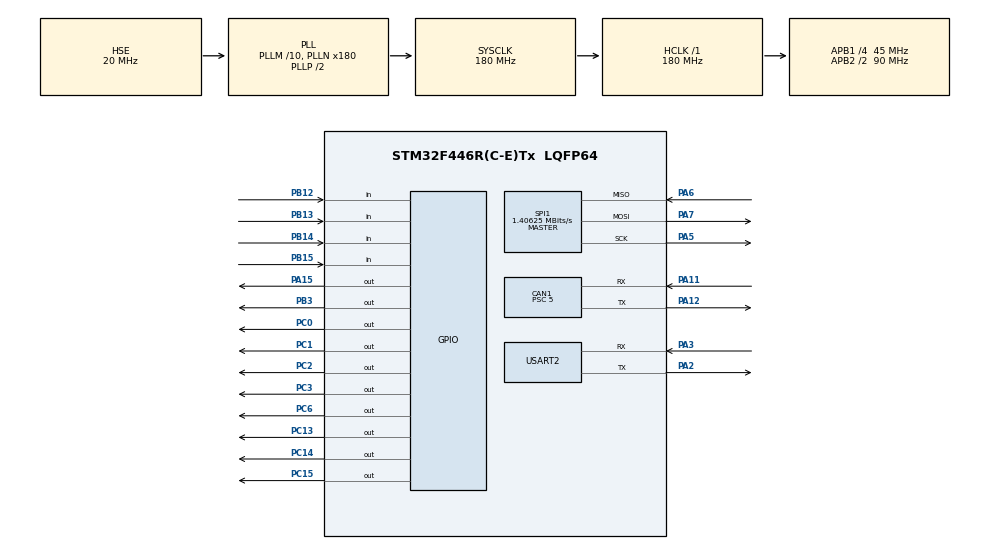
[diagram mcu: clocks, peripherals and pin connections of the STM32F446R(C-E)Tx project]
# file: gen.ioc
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CAN1.ABOM=ENABLE
CAN1.AWUM=ENABLE
CAN1.BS1=CAN_BS1_13TQ
CAN1.BS2=CAN_BS2_2TQ
CAN1.CalculateTimeQuantum=111.11111111111111
CAN1.NART=ENABLE
CAN1.Prescaler=5
Dma.Request0=SPI1_RX
Dma.Request1=SPI1_TX
Dma.Request2=USART2_RX
Dma.Request3=USART2_TX
Dma.SPI1_RX.0.Direction=DMA_PERIPH_TO_MEMORY
Dma.SPI1_RX.0.FIFOMode=DMA_FIFOMODE_DISABLE
Dma.SPI1_RX.0.Instance=DMA2_Stream0
Dma.SPI1_RX.0.MemDataAlignment=DMA_MDATAALIGN_BYTE
Dma.SPI1_RX.0.MemInc=DMA_MINC_ENABLE
Dma.SPI1_RX.0.Mode=DMA_NORMAL
Dma.SPI1_RX.0.PeriphDataAlignment=DMA_PDATAALIGN_BYTE
Dma.SPI1_RX.0.PeriphInc=DMA_PINC_DISABLE
Dma.SPI1_RX.0.Priority=DMA_PRIORITY_LOW
Dma.SPI1_TX.1.Direction=DMA_MEMORY_TO_PERIPH
Dma.SPI1_TX.1.FIFOMode=DMA_FIFOMODE_DISABLE
Dma.SPI1_TX.1.Instance=DMA2_Stream3
Dma.SPI1_TX.1.MemDataAlignment=DMA_MDATAALIGN_BYTE
Dma.SPI1_TX.1.MemInc=DMA_MINC_ENABLE
Dma.SPI1_TX.1.Mode=DMA_NORMAL
Dma.SPI1_TX.1.PeriphDataAlignment=DMA_PDATAALIGN_BYTE
Dma.SPI1_TX.1.PeriphInc=DMA_PINC_DISABLE
Dma.SPI1_TX.1.Priority=DMA_PRIORITY_LOW
Dma.USART2_RX.2.Direction=DMA_PERIPH_TO_MEMORY
Dma.USART2_RX.2.FIFOMode=DMA_FIFOMODE_DISABLE
Dma.USART2_RX.2.Instance=DMA1_Stream5
Dma.USART2_RX.2.MemDataAlignment=DMA_MDATAALIGN_BYTE
Dma.USART2_RX.2.MemInc=DMA_MINC_ENABLE
Dma.USART2_RX.2.Mode=DMA_NORMAL
Dma.USART2_RX.2.PeriphDataAlignment=DMA_PDATAALIGN_BYTE
Dma.USART2_RX.2.PeriphInc=DMA_PINC_DISABLE
Dma.USART2_RX.2.Priority=DMA_PRIORITY_LOW
Dma.USART2_TX.3.Direction=DMA_MEMORY_TO_PERIPH
Dma.USART2_TX.3.FIFOMode=DMA_FIFOMODE_DISABLE
Dma.USART2_TX.3.Instance=DMA1_Stream6
Dma.USART2_TX.3.MemDataAlignment=DMA_MDATAALIGN_BYTE
Dma.USART2_TX.3.MemInc=DMA_MINC_ENABLE
Dma.USART2_TX.3.Mode=DMA_NORMAL
Dma.USART2_TX.3.PeriphDataAlignment=DMA_PDATAALIGN_BYTE
Dma.USART2_TX.3.PeriphInc=DMA_PINC_DISABLE
Dma.USART2_TX.3.Priority=DMA_PRIORITY_LOW
FREERTOS.INCLUDE_vTaskDelayUntil=1
FREERTOS.MEMORY_ALLOCATION=1
FREERTOS.Tasks01=LineCalcTask,0,2048,StartLineCalcTask,Default,NULL,Static,LineCalcTaskBuffer,LineCalcTaskControlBlock
FREERTOS.configCHECK_FOR_STACK_OVERFLOW=1
FREERTOS.configUSE_TRACE_FACILITY=1
Mcu.Family=STM32F4
Mcu.Name=STM32F446R(C-E)Tx
Mcu.Package=LQFP64
NVIC.CAN1_RX0_IRQn=true\:5\:0\:false\:false\:true\:true\:true\:true
NVIC.CAN1_TX_IRQn=true\:5\:0\:false\:false\:true\:true\:true\:true
NVIC.DMA1_Stream5_IRQn=true\:5\:0\:false\:false\:true\:true\:false\:true
NVIC.DMA1_Stream6_IRQn=true\:5\:0\:false\:false\:true\:true\:false\:true
NVIC.DMA2_Stream0_IRQn=true\:5\:0\:false\:false\:true\:true\:false\:true
NVIC.DMA2_Stream3_IRQn=true\:5\:0\:false\:false\:true\:true\:false\:true
NVIC.PriorityGroup=NVIC_PRIORITYGROUP_4
NVIC.SPI1_IRQn=true\:5\:0\:false\:false\:true\:true\:true\:true
NVIC.TIM2_IRQn=true\:0\:0\:false\:false\:true\:false\:false\:true
NVIC.TimeBase=TIM2_IRQn
NVIC.TimeBaseIP=TIM2
NVIC.USART2_IRQn=true\:5\:0\:false\:false\:true\:true\:true\:true
PA11.Mode=Master
PA11.Signal=CAN1_RX
PA12.Mode=Master
PA12.Signal=CAN1_TX
PA13.Signal=SYS_JTMS-SWDIO
PA14.Signal=SYS_JTCK-SWCLK
PA15.Signal=GPIO_Output
PA2.Mode=Asynchronous
PA2.Signal=USART2_TX
PA3.Mode=Asynchronous
PA3.Signal=USART2_RX
PA5.Mode=Full_Duplex_Master
PA5.Signal=SPI1_SCK
PA6.Mode=Full_Duplex_Master
PA6.Signal=SPI1_MISO
PA7.Mode=Full_Duplex_Master
PA7.Signal=SPI1_MOSI
PB12.Signal=GPIO_Input
PB13.Signal=GPIO_Input
PB14.Signal=GPIO_Input
PB15.Signal=GPIO_Input
PB3.Signal=GPIO_Output
PC0.Signal=GPIO_Output
PC1.Signal=GPIO_Output
PC13.Signal=GPIO_Output
PC14-OSC32_IN.Signal=GPIO_Output
PC15-OSC32_OUT.Signal=GPIO_Output
PC2.Signal=GPIO_Output
PC3.Signal=GPIO_Output
PC6.Signal=GPIO_Output
PH0-OSC_IN.Mode=HSE-External-Oscillator
PH0-OSC_IN.Signal=RCC_OSC_IN
PH1-OSC_OUT.Mode=HSE-External-Oscillator
PH1-OSC_OUT.Signal=RCC_OSC_OUT
ProjectManager.HeapSize=0x200
ProjectManager.StackSize=0x400
ProjectManager.TargetToolchain=SW4STM32
RCC.AHBFreq_Value=180000000
RCC.APB1CLKDivider=RCC_HCLK_DIV4
RCC.APB1Freq_Value=45000000
RCC.APB1TimFreq_Value=90000000
RCC.APB2CLKDivider=RCC_HCLK_DIV2
RCC.APB2Freq_Value=90000000
RCC.APB2TimFreq_Value=180000000
RCC.CortexFreq_Value=180000000
RCC.HCLKFreq_Value=180000000
RCC.HSE_VALUE=20000000
RCC.HSICalibrationValue=16
RCC.PLLM=10
RCC.PLLN=180
RCC.PLLSourceVirtual=RCC_PLLSOURCE_HSE
RCC.RCC_TIM_PRescaler_Selection=RCC_TIMPRES_DESACTIVATED
RCC.SYSCLKFreq_VALUE=180000000
RCC.SYSCLKSource=RCC_SYSCLKSOURCE_PLLCLK
RCC.USBFreq_Value=180000000
RCC.VCOOutputFreq_Value=360000000
SPI1.BaudRatePrescaler=SPI_BAUDRATEPRESCALER_64
SPI1.CalculateBaudRate=1.40625 MBits/s
SPI1.Direction=SPI_DIRECTION_2LINES
SPI1.Mode=SPI_MODE_MASTER
SPI1.VirtualType=VM_MASTER
USART2.VirtualMode=VM_ASYNC
VP_FREERTOS_VS_CMSIS_V1.Mode=CMSIS_V1
VP_SYS_VS_tim2.Mode=TIM2
board=gen

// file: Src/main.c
/* USER CODE BEGIN Header */
/**
  ******************************************************************************
  * @file           : main.c
  * @brief          : Main program body
  ******************************************************************************
  * @attention
  *
  * <h2><center>&copy; Copyright (c) 2020 STMicroelectronics.
  * All rights reserved.</center></h2>
  *
  * This software component is licensed by ST under Ultimate Liberty license
  * SLA0044, the "License"; You may not use this file except in compliance with
  * the License. You may obtain a copy of the License at:
  *                             www.st.com/SLA0044
  *
  ******************************************************************************
  */
/* USER CODE END Header */

#include "main.h"
#include "cmsis_os.h"
#include "can.h"
#include "dma.h"
#include "spi.h"
#include "usart.h"
#include "gpio.h"

/* USER CODE BEGIN Includes */
#include <system_init.h>
/* USER CODE END Includes */

void SystemClock_Config(void);
void MX_FREERTOS_Init(void);

int main(void)
{

  /* MCU Configuration--------------------------------------------------------*/

  /* Reset of all peripherals, Initializes the Flash interface and the Systick. */
  HAL_Init();

  /* Configure the system clock */
  SystemClock_Config();

  /* USER CODE BEGIN SysInit */
  system_init();
  /* USER CODE END SysInit */

  /* Initialize all configured peripherals */
  MX_GPIO_Init();
  MX_DMA_Init();
  MX_SPI1_Init();
  MX_CAN1_Init();
  MX_USART2_UART_Init();
  /* USER CODE BEGIN 2 */
  can_start();
  /* USER CODE END 2 */

  /* Call init function for freertos objects (in freertos.c) */
  MX_FREERTOS_Init();

  /* Start scheduler */
  osKernelStart();

  /* We should never get here as control is now taken by the scheduler */

  /* Infinite loop */
  while (1)
  {

  }
}

void SystemClock_Config(void)
{
  RCC_OscInitTypeDef RCC_OscInitStruct = {0};
  RCC_ClkInitTypeDef RCC_ClkInitStruct = {0};

  /** Configure the main internal regulator output voltage
  */
  __HAL_RCC_PWR_CLK_ENABLE();
  __HAL_PWR_VOLTAGESCALING_CONFIG(PWR_REGULATOR_VOLTAGE_SCALE1);
  /** Initializes the CPU, AHB and APB busses clocks
  */
  RCC_OscInitStruct.OscillatorType = RCC_OSCILLATORTYPE_HSE;
  RCC_OscInitStruct.HSEState = RCC_HSE_ON;
  RCC_OscInitStruct.PLL.PLLState = RCC_PLL_ON;
  RCC_OscInitStruct.PLL.PLLSource = RCC_PLLSOURCE_HSE;
  RCC_OscInitStruct.PLL.PLLM = 10;
  RCC_OscInitStruct.PLL.PLLN = 180;
  RCC_OscInitStruct.PLL.PLLP = RCC_PLLP_DIV2;
  RCC_OscInitStruct.PLL.PLLQ = 2;
  RCC_OscInitStruct.PLL.PLLR = 2;
  if (HAL_RCC_OscConfig(&RCC_OscInitStruct) != HAL_OK)
  {
    Error_Handler();
  }
  /** Activate the Over-Drive mode
  */
  if (HAL_PWREx_EnableOverDrive() != HAL_OK)
  {
    Error_Handler();
  }
  /** Initializes the CPU, AHB and APB busses clocks
  */
  RCC_ClkInitStruct.ClockType = RCC_CLOCKTYPE_HCLK|RCC_CLOCKTYPE_SYSCLK
                              |RCC_CLOCKTYPE_PCLK1|RCC_CLOCKTYPE_PCLK2;
  RCC_ClkInitStruct.SYSCLKSource = RCC_SYSCLKSOURCE_PLLCLK;
  RCC_ClkInitStruct.AHBCLKDivider = RCC_SYSCLK_DIV1;
  RCC_ClkInitStruct.APB1CLKDivider = RCC_HCLK_DIV4;
  RCC_ClkInitStruct.APB2CLKDivider = RCC_HCLK_DIV2;

  if (HAL_RCC_ClockConfig(&RCC_ClkInitStruct, FLASH_LATENCY_5) != HAL_OK)
  {
    Error_Handler();
  }
}

void HAL_TIM_PeriodElapsedCallback(TIM_HandleTypeDef *htim)
{
  if (htim->Instance == TIM2) {
    HAL_IncTick();
  }
}

void Error_Handler(void)
{
  __disable_irq();
  while (1) {}
}

/************************ (C) COPYRIGHT STMicroelectronics *****END OF FILE****/

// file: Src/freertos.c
/* USER CODE BEGIN Header */
/**
 ******************************************************************************
 * File Name          : freertos.c
 * Description        : Code for freertos applications
 ******************************************************************************
 * @attention
 *
 * <h2><center>&copy; Copyright (c) 2020 STMicroelectronics.
 * All rights reserved.</center></h2>
 *
 * This software component is licensed by ST under Ultimate Liberty license
 * SLA0044, the "License"; You may not use this file except in compliance with
 * the License. You may obtain a copy of the License at:
 *                             www.st.com/SLA0044
 *
 ******************************************************************************
 */
/* USER CODE END Header */

#include "FreeRTOS.h"

#include "cmsis_os.h"
#include "main.h"
#include "task.h"

osThreadId LineCalcTaskHandle;
uint32_t LineCalcTaskBuffer[2048];
osStaticThreadDef_t LineCalcTaskControlBlock;

/* USER CODE BEGIN FunctionPrototypes */
void runLineCalcTask(void);
void runDebugTask(void);
/* USER CODE END FunctionPrototypes */

void StartLineCalcTask(void const* argument);

void MX_FREERTOS_Init(void); /* (MISRA C 2004 rule 8.1) */

/* GetIdleTaskMemory prototype (linked to static allocation support) */
void vApplicationGetIdleTaskMemory(StaticTask_t** ppxIdleTaskTCBBuffer,
                                   StackType_t** ppxIdleTaskStackBuffer,
                                   uint32_t* pulIdleTaskStackSize);

/* Hook prototypes */
void vApplicationStackOverflowHook(xTaskHandle xTask, signed char* pcTaskName);

/* USER CODE BEGIN 4 */
__weak void vApplicationStackOverflowHook(xTaskHandle xTask, signed char* pcTaskName) {
    /* Run time stack overflow checking is performed if
    configCHECK_FOR_STACK_OVERFLOW is defined to 1 or 2. This hook function is
    called if a stack overflow is detected. */
}
/* USER CODE END 4 */

/* USER CODE BEGIN GET_IDLE_TASK_MEMORY */
static StaticTask_t xIdleTaskTCBBuffer;
static StackType_t xIdleStack[configMINIMAL_STACK_SIZE];

void vApplicationGetIdleTaskMemory(StaticTask_t** ppxIdleTaskTCBBuffer,
                                   StackType_t** ppxIdleTaskStackBuffer,
                                   uint32_t* pulIdleTaskStackSize) {
    *ppxIdleTaskTCBBuffer   = &xIdleTaskTCBBuffer;
    *ppxIdleTaskStackBuffer = &xIdleStack[0];
    *pulIdleTaskStackSize   = configMINIMAL_STACK_SIZE;
    /* place for user code */
}
/* USER CODE END GET_IDLE_TASK_MEMORY */

void MX_FREERTOS_Init(void) {

    /* Create the thread(s) */
    /* definition and creation of LineCalcTask */
    osThreadStaticDef(LineCalcTask, StartLineCalcTask, osPriorityNormal, 0, 2048,
                      LineCalcTaskBuffer, &LineCalcTaskControlBlock);
    LineCalcTaskHandle = osThreadCreate(osThread(LineCalcTask), NULL);

}

void StartLineCalcTask(void const* argument) {
    /* USER CODE BEGIN StartLineCalcTask */
    UNUSED(argument);
    runLineCalcTask();
    vTaskDelete(NULL);
    /* USER CODE END StartLineCalcTask */
}

/************************ (C) COPYRIGHT STMicroelectronics *****END OF FILE****/
